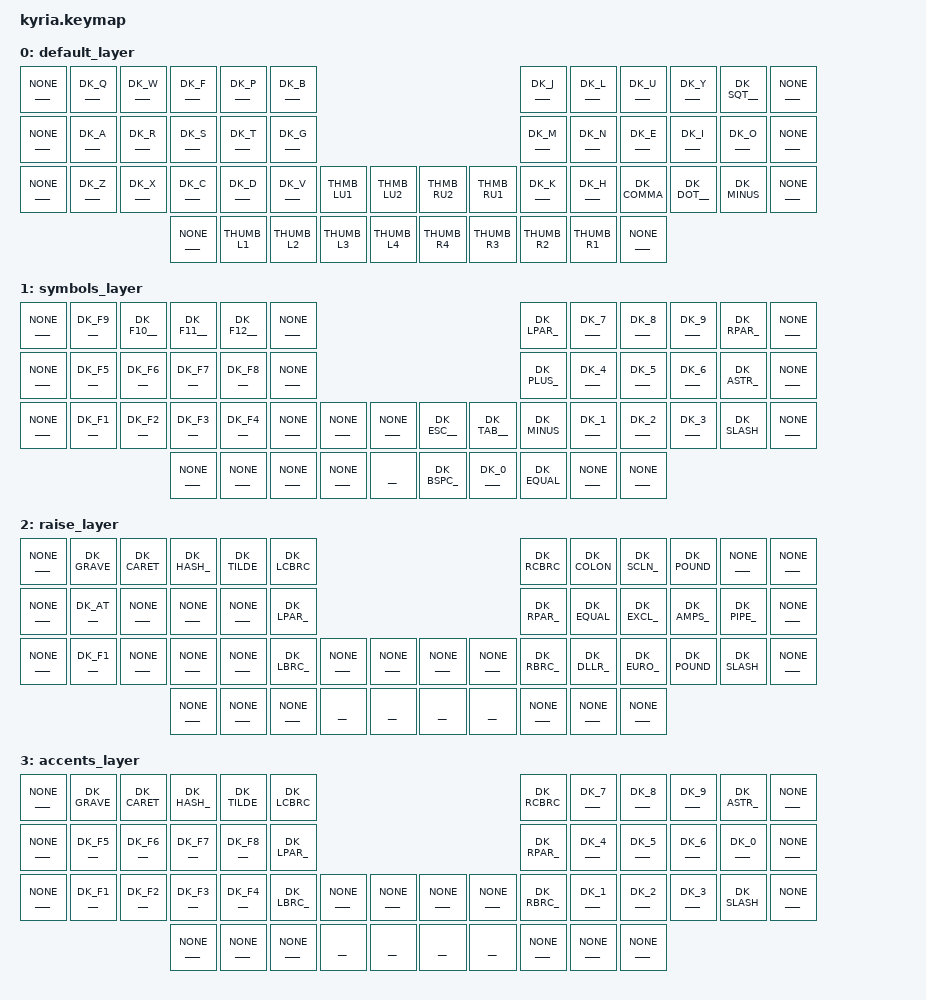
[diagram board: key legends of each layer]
/*
 * Copyright (c) 2020 The ZMK Contributors
 *
 * SPDX-License-Identifier: MIT
 */

#include <behaviors.dtsi>
#include <dt-bindings/zmk/keys.h>
#include "mac_iso_danish.keycodes"

/ {

    behaviors {
        hm: homerow_mods {
            compatible = "zmk,behavior-hold-tap";
            label = "HOMEROW_MODS";
            #binding-cells = <2>;
            tapping-term-ms = <300>;
            quick_tap_ms = <300>;
            flavor = "tap-preferred";
            bindings = <&kp>, <&kp>;
        };
        tl: thumb_layers {
            compatible = "zmk,behavior-hold-tap";
            label = "THUMB_LAYERS";
            #binding-cells = <2>;
            tapping-term-ms = <175>;
            quick_tap_ms = <175>;
            flavor = "balanced";
            bindings = <&kp>, <&kp>;
        };
    };

#include "keymap.keycodes"

	keymap {
		compatible = "zmk,keymap";

		default_layer {
			bindings = <
// .--------+--------+--------+--------+--------+--------.                                      .--------+--------+--------+--------+--------+--------.
    NONE____ DK_Q____ DK_W____ DK_F____ DK_P____ DK_B____                                        DK_J____ DK_L____ DK_U____ DK_Y____ DK_SQT__ NONE____ 
// |--------+--------+--------+--------+--------+--------|                                      |--------+--------+--------+--------+--------+--------|
    NONE____ DK_A____ DK_R____ DK_S____ DK_T____ DK_G____                                        DK_M____ DK_N____ DK_E____ DK_I____ DK_O____ NONE____ 
// |--------+--------+--------+--------+--------+--------+--------+--------.  .--------+--------+--------+--------+--------+--------+--------+--------|
    NONE____ DK_Z____ DK_X____ DK_C____ DK_D____ DK_V____ THMB_LU1 THMB_LU2    THMB_RU2 THMB_RU1 DK_K____ DK_H____ DK_COMMA DK_DOT__ DK_MINUS NONE____ 
// '--------+--------+--------+--------+--------+--------+--------+--------|  |--------+--------+--------+--------+--------+--------+--------+--------'
                               NONE____ THUMB_L1 THUMB_L2 THUMB_L3 THUMB_L4    THUMB_R4 THUMB_R3 THUMB_R2 THUMB_R1 NONE____ 
//                            '--------+--------+--------+--------+--------'  '--------+--------+--------+--------+--------'
			>;
			sensor-bindings = <&inc_dec_kp C_VOL_UP C_VOL_DN &inc_dec_kp PG_UP PG_DN>;
		};

		symbols_layer {
			bindings = <
// .--------+--------+--------+--------+--------+--------.                                      .--------+--------+--------+--------+--------+--------.
    NONE____ DK_F9___ DK_F10__ DK_F11__ DK_F12__ NONE____                                        DK_LPAR_ DK_7____ DK_8____ DK_9____ DK_RPAR_ NONE____ 
// |--------+--------+--------+--------+--------+--------|                                      |--------+--------+--------+--------+--------+--------|
    NONE____ DK_F5___ DK_F6___ DK_F7___ DK_F8___ NONE____                                        DK_PLUS_ DK_4____ DK_5____ DK_6____ DK_ASTR_ NONE____   
// |--------+--------+--------+--------+--------+--------+--------+--------.  .--------+--------+--------+--------+--------+--------+--------+--------|
    NONE____ DK_F1___ DK_F2___ DK_F3___ DK_F4___ NONE____ NONE____ NONE____    DK_ESC__ DK_TAB__ DK_MINUS DK_1____ DK_2____ DK_3____ DK_SLASH NONE____ 
// '--------+--------+--------+--------+--------+--------+--------+--------|  |--------+--------+--------+--------+--------+--------+--------+--------'
                               NONE____ NONE____ NONE____ NONE____ ________    DK_BSPC_ DK_0____ DK_EQUAL NONE____ NONE____ 
//                            '--------+--------+--------+--------+--------'  '--------+--------+--------+--------+--------'
			>;
			sensor-bindings = <&inc_dec_kp C_VOL_UP C_VOL_DN &inc_dec_kp PG_UP PG_DN>;
		};

		raise_layer {
			bindings = <
// .--------+--------+--------+--------+--------+--------.                                      .--------+--------+--------+--------+--------+--------.
    NONE____ DK_GRAVE DK_CARET DK_HASH_ DK_TILDE DK_LCBRC                                        DK_RCBRC DK_COLON DK_SCLN_ DK_POUND NONE____ NONE____ 
// |--------+--------+--------+--------+--------+--------|                                      |--------+--------+--------+--------+--------+--------|
    NONE____ DK_AT___ NONE____ NONE____ NONE____ DK_LPAR_                                        DK_RPAR_ DK_EQUAL DK_EXCL_ DK_AMPS_ DK_PIPE_ NONE____   
// |--------+--------+--------+--------+--------+--------+--------+--------.  .--------+--------+--------+--------+--------+--------+--------+--------|
    NONE____ DK_F1___ NONE____ NONE____ NONE____ DK_LBRC_ NONE____ NONE____    NONE____ NONE____ DK_RBRC_ DK_DLLR_ DK_EURO_ DK_POUND DK_SLASH NONE____ 
// '--------+--------+--------+--------+--------+--------+--------+--------|  |--------+--------+--------+--------+--------+--------+--------+--------'
                               NONE____ NONE____ NONE____ ________ ________    ________ ________ NONE____ NONE____ NONE____ 
//                            '--------+--------+--------+--------+--------'  '--------+--------+--------+--------+--------'
			>;
			sensor-bindings = <&inc_dec_kp C_VOL_UP C_VOL_DN &inc_dec_kp PG_UP PG_DN>;
		};

		accents_layer {
			bindings = <
// .--------+--------+--------+--------+--------+--------.                                      .--------+--------+--------+--------+--------+--------.
    NONE____ DK_GRAVE DK_CARET DK_HASH_ DK_TILDE DK_LCBRC                                        DK_RCBRC DK_7____ DK_8____ DK_9____ DK_ASTR_ NONE____ 
// |--------+--------+--------+--------+--------+--------|                                      |--------+--------+--------+--------+--------+--------|
    NONE____ DK_F5___ DK_F6___ DK_F7___ DK_F8___ DK_LPAR_                                        DK_RPAR_ DK_4____ DK_5____ DK_6____ DK_0____ NONE____   
// |--------+--------+--------+--------+--------+--------+--------+--------.  .--------+--------+--------+--------+--------+--------+--------+--------|
    NONE____ DK_F1___ DK_F2___ DK_F3___ DK_F4___ DK_LBRC_ NONE____ NONE____    NONE____ NONE____ DK_RBRC_ DK_1____ DK_2____ DK_3____ DK_SLASH NONE____ 
// '--------+--------+--------+--------+--------+--------+--------+--------|  |--------+--------+--------+--------+--------+--------+--------+--------'
                               NONE____ NONE____ NONE____ ________ ________    ________ ________ NONE____ NONE____ NONE____ 
//                            '--------+--------+--------+--------+--------'  '--------+--------+--------+--------+--------'
			>;
			sensor-bindings = <&inc_dec_kp C_VOL_UP C_VOL_DN &inc_dec_kp PG_UP PG_DN>;
		};
	};
};

